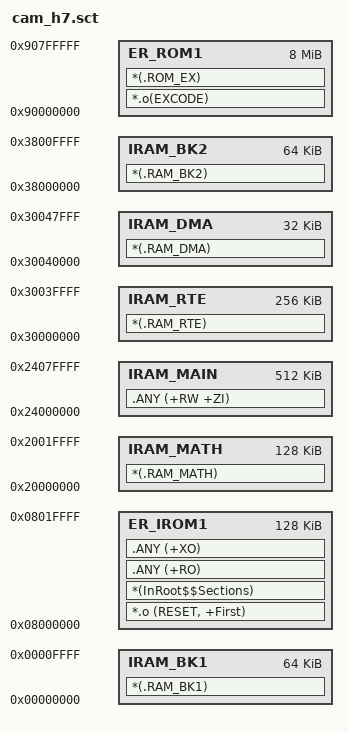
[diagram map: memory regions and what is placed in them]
; *************************************************************
; *** Scatter-Loading Description File generated by uVision ***
; *************************************************************

LR_IROM1 0x08000000 0x20000  {    ; load region size_region
  ER_IROM1 0x08000000 0x20000  {  ; load address = execution address
   *.o (RESET, +First)
   *(InRoot$$Sections)
   .ANY (+RO)
   .ANY (+XO)
  }
  IRAM_BK1 0x00000000 0x00010000  {  ; TCM RAM 400MHz ITCM 64K
   *(.RAM_BK1)
  }
  IRAM_MATH 0x20000000 0X00020000 {  ; TCM RAM 400MHz DTCM 128K
   *(.RAM_MATH)
  }
  IRAM_MAIN 0x24000000 0x00080000 {  ; AXI SRAM 200MHz 512K
   .ANY (+RW +ZI)
  }

  IRAM_RTE 0x30000000 0X00040000 {  ; SRAM1+SRAM2 256K AHB SRAM D2 200MHz
   *(.RAM_RTE)
  }

  IRAM_DMA 0x30040000 0X00008000 {  ;  AHB SRAM D2 200MHz RAM3 32K
   *(.RAM_DMA)
  }

  IRAM_BK2 0x38000000 0X00010000 {  ;  AHB RAM D3 200MHz SRAM4 64K
   *(.RAM_BK2)
  }

}

LR_ROM1 0x90000000 0x00800000  {
  ER_ROM1 0x90000000 0x00800000  {  ; load address = execution address
	*.o(EXCODE)
	*(.ROM_EX)
  }
}
